# CH643 register map
Vendor: WCH Ltd.; File version: 1.3
CH643 View File
Registers are 32-bit, read-write, reset 0x0 unless marked. A register's access mark holds for its fields unless they carry their own. Offsets are from the block's base; lines under a group give offsets from that group; [hi:lo] are bit positions; {n}, {i} and the like mark numbered series; 'fields as' and 'values as' point back to an identical list; <NAME> marks a mode.

## Memory map
0x1FFFF7E0 ESIG size 0x200 — ESIG configuration
0x40000000 TIM2 size 0x400
0x40000400 TIM3 size 0x400 — General purpose timer
0x40002C00 WWDG size 0x400 — Window watchdog
0x40003000 IWDG size 0x400 — Independent watchdog
0x40004400 USART2 size 0x400
0x40004800 USART3 size 0x400
0x40004C00 UART4 size 0x400
0x40005400 I2C1 size 0x400 — Inter integrated circuit
0x40007000 PWR size 0x400 — Power control
0x40010000 AFIO size 0x400 — Alternate function I/O
0x40010400 EXTI size 0x400
0x40010800 GPIOA size 0x400 — General purpose I/O
0x40010C00 GPIOB size 0x400
0x40011000 GPIOC size 0x400
0x40012400 ADC size 0x400 — Analog to digital converter
0x40012C00 TIM1 size 0x400 — Advanced timer
0x40013000 SPI1 size 0x400 — Serial peripheral interface
0x40013800 USART1 size 0x400 — Universal synchronous asynchronous receiver transmitter
0x40020000 DMA size 0x400 — DMA controller
0x40021000 RCC size 0x400 — Reset and clock control
0x40022000 FLASH size 0x400
0x40023400 USBFS size 0x400 — USB register
0x40026000 OPA size 0x400 — OPA configuration
0x40026400 AWU size 0x200 — AWU configuration
0x40026800 LEDPWM size 0x200 — LEDPWM configuration
0x40027000 USBPD size 0x200 — USBPD configuration
0xE000D000 DBG size 0x400 — Debug support
0xE000E000 PFIC size 0x1100 — Programmable Fast Interrupt Controller

## Interrupts
16 WWDG — Window Watchdog interrupt
17 PVD (PWR) — PVD through EXTI line detection interrupt
18 FLASH — Flash global interrupt
19 LEDPWM — LEDPWM global interrupt
20 EXTI7_0 (EXTI) — EXTI Line[7:0] interrupt
21 AWU — AWU global interrupt
22 DMA_Channel1 (DMA) — DMA Channel1 global interrupt
23 DMA_Channel2 (DMA) — DMA Channel2 global interrupt
24 DMA_Channel3 (DMA) — DMA Channel3 global interrupt
25 DMA_Channel4 (DMA) — DMA Channel4 global interrupt
26 DMA_Channel5 (DMA) — DMA Channel5 global interrupt
27 DMA_Channel6 (DMA) — DMA Channel6 global interrupt
28 DMA_Channel7 (DMA) — DMA Channel7 global interrupt
29 ADC1 (ADC) — ADC global interrupt
30 I2C1_EV (I2C1) — I2C1 event interrupt
31 I2C1_ER (I2C1) — I2C1 error interrupt
32 USART1 — USART1 global interrupt
33 SPI1 — SPI1 global interrupt
34 TIM1_BRK (TIM1) — TIM1 Break interrupt
35 TIM1_UP_ (TIM1) — TIM1 Update interrupt
36 TIM1_TRG_COM (TIM1) — TIM1 Trigger and Commutation interrupts
37 TIM1_CC (TIM1) — TIM1 Capture Compare interrupt
38 TIM2_UP_ (TIM2) — TIM2 Update interrupt
39 USART2 — USART2 global interrupt
40 EXTI15_8 (EXTI) — EXTI Line[15:8] interrupts
41 EXTI25_16 (EXTI) — EXTI Line[25:16] interrupts
42 USART3 — USART3 global interrupt
43 UART4 — UART4 global interrupt
44 DMA_Channel8 (DMA) — DMA Channel8 global interrupt
45 USBFS
46 USBFS_WKUP (USBFS)
49 USBPD — USBPD global interrupt
50 USBPD_WKUP (USBPD) — USBPD_WKUP global interrupt
51 TIM2_CC (TIM2) — TIM2 Capture Compare interrupt
52 TIM2_TRG_COM (TIM2) — TIM2 Trigger and Commutation interrupts
53 TIM2_BRK (TIM2) — TIM2 Break interrupt
54 TIM3 — TIM3 global interrupt

## PWR — Power control
Base 0x40007000
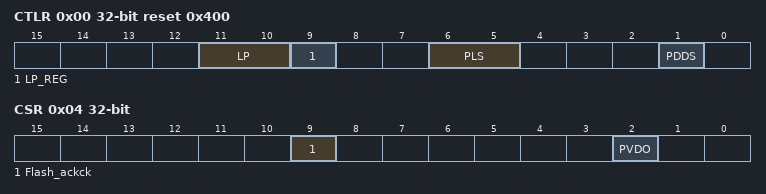
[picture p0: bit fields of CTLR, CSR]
0x00 CTLR reset 0x400 — Power control register (PWR_CTLR)
  [11:10] LP — LP Config
  [9] LP_REG — LP_REG enable
  [6:5] PLS — PVD Level Selection
  [1] PDDS — Power Down Deep Sleep
0x04 CSR ro — Power control register (PWR_CSR)
  [9] Flash_ackck — Flash Status flag
  [2] PVDO — PVD Output

## RCC — Reset and clock control
Base 0x40021000
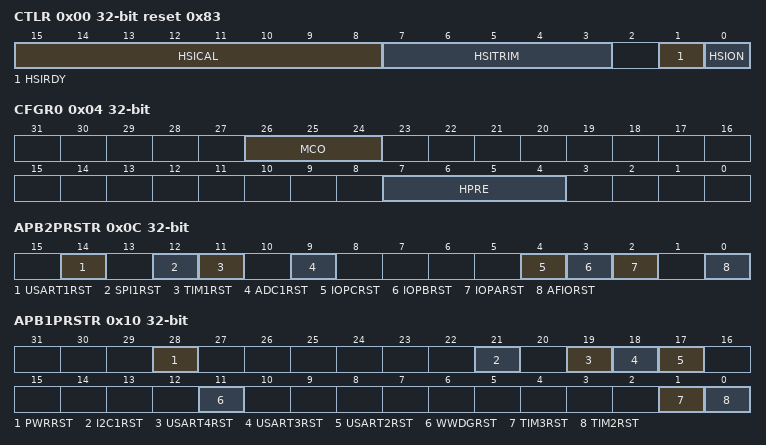
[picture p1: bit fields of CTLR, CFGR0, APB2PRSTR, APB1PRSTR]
0x00 CTLR access per field reset 0x83 — Clock control register
  [15:8] HSICAL ro — Internal High Speed clock Calibration
  [7:3] HSITRIM rw — Internal High Speed clock trimming
  [1] HSIRDY ro — Internal High Speed clock ready flag
  [0] HSION rw — Internal High Speed clock enable
0x04 CFGR0 — Clock configuration register (RCC_CFGR0)
  [26:24] MCO — Microcontroller clock output
  [7:4] HPRE — AHB prescaler
0x0C APB2PRSTR — PB2 peripheral reset register (RCC_APB2PRSTR)
  [14] USART1RST — USART1 reset
  [12] SPI1RST — SPI 1 reset
  [11] TIM1RST — TIM1 timer reset
  [9] ADC1RST — ADC 1 interface reset
  [4] IOPCRST — IO port C reset
  [3] IOPBRST — IO port B reset
  [2] IOPARST — IO port A reset
  [0] AFIORST — Alternate function I/O reset
0x10 APB1PRSTR — PB1 peripheral reset register (RCC_APB1PRSTR)
  [28] PWRRST — Power interface reset
  [21] I2C1RST — I2C1 reset
  [19] USART4RST — USART 4 reset
  [18] USART3RST — USART 3 reset
  [17] USART2RST — USART 2 reset
  [11] WWDGRST — Window watchdog reset
  [1] TIM3RST — Timer 3 reset
  [0] TIM2RST — Timer 2 reset
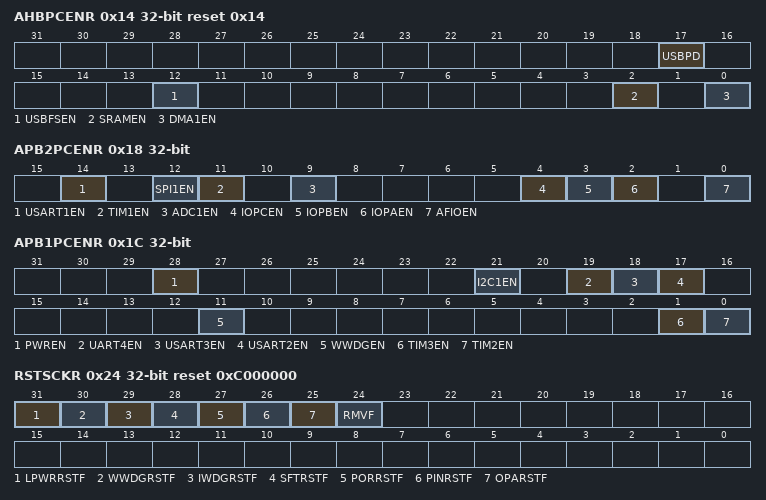
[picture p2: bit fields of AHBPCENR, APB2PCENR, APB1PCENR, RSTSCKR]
0x14 AHBPCENR reset 0x14 — HB Peripheral Clock enable register (RCC_AHBPCENR)
  [17] USBPD — USBPD clock enable
  [12] USBFSEN — USBFS clock enable
  [2] SRAMEN — SRAM interface clock enable
  [0] DMA1EN — DMA clock enable
0x18 APB2PCENR — PB2 peripheral clock enable register (RCC_APB2PCENR)
  [14] USART1EN — USART1 clock enable
  [12] SPI1EN — SPI 1 clock enable
  [11] TIM1EN — TIM1 Timer clock enable
  [9] ADC1EN — ADC1 interface clock enable
  [4] IOPCEN — I/O port C clock enable
  [3] IOPBEN — I/O port B clock enable
  [2] IOPAEN — I/O port A clock enable
  [0] AFIOEN — Alternate function I/O clock enable
0x1C APB1PCENR — PB1 peripheral clock enable register (RCC_APB1PCENR)
  [28] PWREN — Power interface clock enable
  [21] I2C1EN — I2C 1 clock enable
  [19] UART4EN — UART 4 clock enable
  [18] USART3EN — USART 3 clock enable
  [17] USART2EN — USART 2 clock enable
  [11] WWDGEN — Window watchdog clock enable
  [1] TIM3EN — Timer 3 clock enable
  [0] TIM2EN — Timer 2 clock enable
0x24 RSTSCKR reset 0xC000000 — Control/status register (RCC_RSTSCKR)
  [31] LPWRRSTF — Low-power reset flag
  [30] WWDGRSTF — Window watchdog reset flag
  [29] IWDGRSTF — Independent watchdog reset flag
  [28] SFTRSTF — Software reset flag
  [27] PORRSTF — POR/PDR reset flag
  [26] PINRSTF — PIN reset flag
  [25] OPARSTF — OPA reset flag
  [24] RMVF — Remove reset flag
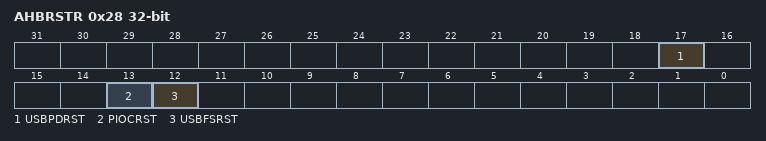
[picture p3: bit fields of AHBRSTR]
0x28 AHBRSTR — HB reset register (RCC_APHBRSTR)
  [17] USBPDRST — USBPD reset
  [13] PIOCRST — PIOC reset
  [12] USBFSRST — USBFS reset
